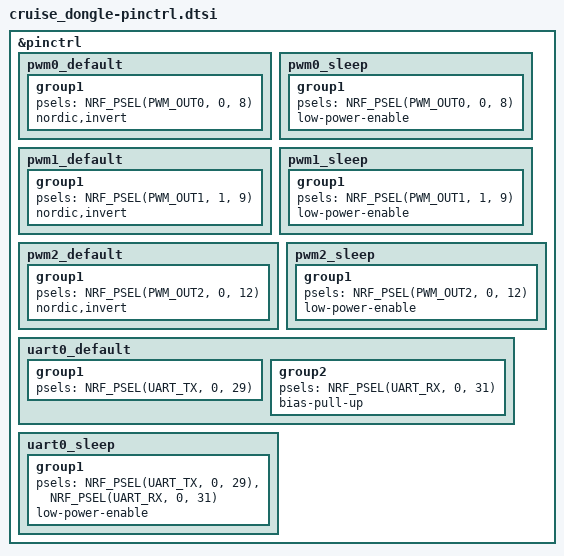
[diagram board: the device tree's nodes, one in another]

&pinctrl {
	pwm0_default: pwm0_default {
		group1 {
			psels = <NRF_PSEL(PWM_OUT0, 0, 8)>;
			nordic,invert;
		};
	};

	pwm0_sleep: pwm0_sleep {
		group1 {
			psels = <NRF_PSEL(PWM_OUT0, 0, 8)>;
			low-power-enable;
		};
	};

	pwm1_default: pwm1_default {
		group1 {
			psels = <NRF_PSEL(PWM_OUT1, 1, 9)>;
			nordic,invert;
		};
	};

	pwm1_sleep: pwm1_sleep {
		group1 {
			psels = <NRF_PSEL(PWM_OUT1, 1, 9)>;
			low-power-enable;
		};
	};

	pwm2_default: pwm2_default {
		group1 {
			psels = <NRF_PSEL(PWM_OUT2, 0, 12)>;
			nordic,invert;
		};
	};

	pwm2_sleep: pwm2_sleep {
		group1 {
			psels = <NRF_PSEL(PWM_OUT2, 0, 12)>;
			low-power-enable;
		};
	};
	
	uart0_default: uart0_default {
		group1 {
			psels = <NRF_PSEL(UART_TX, 0, 29)>;
				// <NRF_PSEL(UART_RTS, 1, 15)>;
		};
		group2 {
			psels = <NRF_PSEL(UART_RX, 0, 31)>;
				// <NRF_PSEL(UART_CTS, 0, 02)>;
			bias-pull-up;
		};
	};

	uart0_sleep: uart0_sleep {
		group1 {
			psels = <NRF_PSEL(UART_TX, 0, 29)>,
				<NRF_PSEL(UART_RX, 0, 31)>;
				// <NRF_PSEL(UART_RTS, 1, 15)>,
				// <NRF_PSEL(UART_CTS, 0, 02)>;
			low-power-enable;
		};
	};
};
